# apollo4p register map
Vendor: Ambiq Micro; Series: Apollo; File version: 1.0
CPU: CM4 r1p0, little endian, MPU, FPU, I-cache, D-cache, VTOR, ITCM, DTCM, 3 interrupt priority bits, 0 interrupts
Registers are 32-bit, read-write, reset 0x0 unless marked. A register's access mark holds for its fields unless they carry their own. Offsets are from the block's base; [hi:lo] are bit positions; {n}, {i} and the like mark numbered series.

## DC — Display Controller
Base 0x400A0000
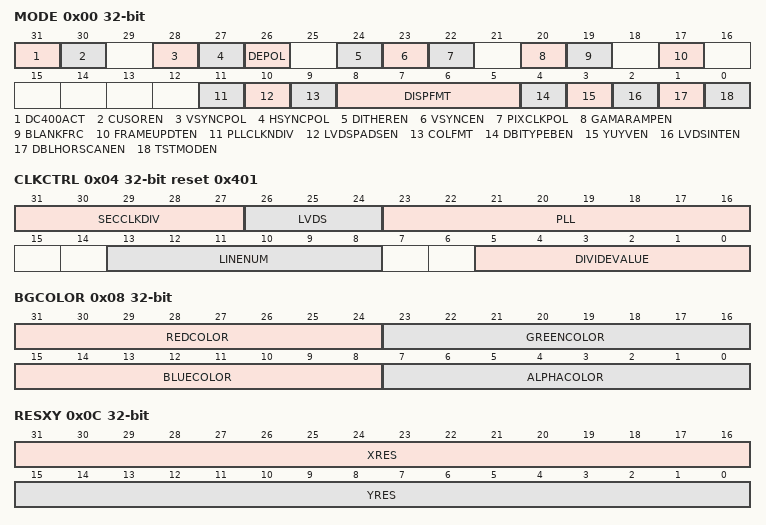
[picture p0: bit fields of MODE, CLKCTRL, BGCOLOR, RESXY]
0x00 MODE — General control register that activates the NEMAp|dc400 controller and various parameters, sets the timing signals' polarity, activates the global look-up table for gamma correction and chooses the output display formats to meet LCD color specifications.
  [31] DC400ACT — When set to 1, the dc400 controller is activated
  [30] CUSOREN — When set to 1, programmable cursor is enabled
  [28] VSYNCPOL — Defines VSYNC polarity
    1=VSYNC_NEG (VSYNC polarity is negative); 0=VSYNC_POS (VSYNC polarity is positive)
  [27] HSYNCPOL — Defines HSYNC polarity
    1=HSYNC_NEG (HSYNC polarity is negative); 0=HSYNC_POS (HSYNC polarity is positive)
  [26] DEPOL — Defines DE polarity
    1=DE_NEG (DE polarity is negative); 0=DE_POS (DE polarity is positive)
  [24] DITHEREN — When set to 1, dithering is enabled
  [23] VSYNCEN — When set to 1, VSYNC for a single cycle per line is enabled
  [22] PIXCLKPOL — Defines Pixel Clock out polarity
    1=POL_NEG (Pixel Clock out polarity is negative); 0=POL_POS (Pixel Clock out polarity is positive)
  [20] GAMARAMPEN — When set to 1, gamma ramp is enabled
  [19] BLANKFRC — When set to 1, forces output to blank
  [17] FRAMEUPDTEN — When set to 1, single frame update is enabled
  [11] PLLCLKNDIV — When set to 1, PLL_CLK is not divided
  [10] LVDSPADSEN — When set to 1, LVDS output pads are enabled
  [9] COLFMT — Output color format:
    1=YUV_EN (YUV/YCbCr format is enabled); 0=RGB_EN (RGB format is enabled)
  [8:5] DISPFMT — Display data format
    0=DPI (DPI Interface); 1=BYTE3 (Byte-3 beat Interface); 2=BYTE4 (Byte-4 beat (RGBX) Interface); 3=SERIAL (Two phase serial 12-bit); 4=LVDS2 (LVDS 24-bit unbalanced single pixel format 2); 5=LVDS1 (LVDS 24-bit unbalanced single pixel format 1); 6=YUYV (YUYV (16-bit mode)); 7=BT656; 8=JDI (JDI MIP)
  [4] DBITYPEBEN — When set to 1, DBI Type-B interface is enabled
  [3] YUYVEN — When set to 1, the following output color formats are enabled : Byte-3 beat Interface enabled, Byte-4 beat (RGBX) Interface enabled, Two phase serial 12-bit enabled, YUYV (16-bit mode) enabled, BT.656 enabled, JDI MIP enabled
  [2] LVDSINTEN — When set to 1, LVDS interface is enabled
  [1] DBLHORSCANEN — When set to 1, double horizontal scan is enabled
  [0] TSTMODEN — When set to 1, test mode is enabled
0x04 CLKCTRL reset 0x401 — Setup proper timing with divisor control bits and specify the number of lines to be prefetched before the start of frame.
  [31:27] SECCLKDIV — Value of secondary clock divider
    0=SDIV_0 (No division); 1=SDIV_1 (No division); {v}=SDIV_{v} (Divided by {v}) (v=2..15)
  [26:24] LVDS — Clock phase shift value for LVDS operation
  [23:16] PLL — Select PLL Clock
  [13:8] LINENUM — Number of lines to be prefetched before starting the frame through DMA. Maximum value is 32
  [5:0] DIVIDEVALUE — Value of first clock divider
    0=FDIV_0 (Divided by 0); {v}=FDIV_{v} (Divided by {v}) (v=2..31)
0x08 BGCOLOR — Specifies the main background color.
  [31:24] REDCOLOR — Color red is used as background color
  [23:16] GREENCOLOR — Color green is used as background color
  [15:8] BLUECOLOR — Color blue is used as background color
  [7:0] ALPHACOLOR — Color alpha is used as background color
0x0C RESXY — Specifies the main X and Y resolutions.
  [31:16] XRES — Value of X resolution in pixels
  [15:0] YRES — Value of Y resolution in pixels
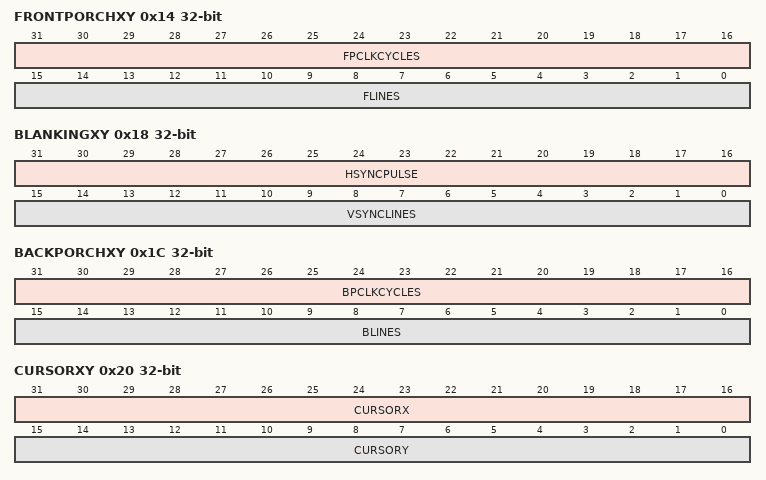
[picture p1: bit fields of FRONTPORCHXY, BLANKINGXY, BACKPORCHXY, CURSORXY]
0x14 FRONTPORCHXY — Specifies the X and Y dimensions for the Front Porch.
  [31:16] FPCLKCYCLES — Specify the pixel clock cycles for the front porch X dimension
  [15:0] FLINES — Specify the number of lines for the front porch Y dimension
0x18 BLANKINGXY — Specifies the X and Y dimensions for the Blanking Period.
  [31:16] HSYNCPULSE — Specify the HSYNC pulse length for the X dimension blanking period
  [15:0] VSYNCLINES — Specify the VSYNC lines for the Y dimension blanking period
0x1C BACKPORCHXY — Specifies the X and Y dimensions for the Back Porch.
  [31:16] BPCLKCYCLES — Specify the pixel clock cycles for the back porch X dimension
  [15:0] BLINES — Specify the number of lines for the back porch Y dimension
0x20 CURSORXY — Specifies the cursor's start X and Y coordinates.
  [31:16] CURSORX — Specify cursor's X dimension
  [15:0] CURSORY — Specify cursor's Y dimension
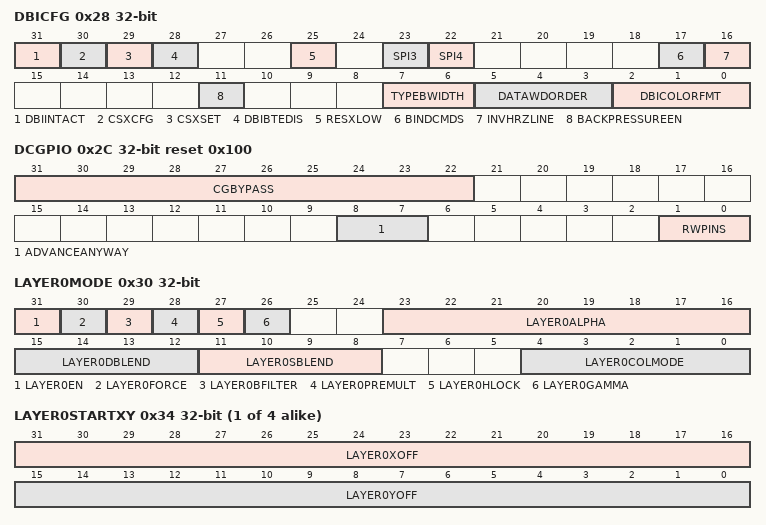
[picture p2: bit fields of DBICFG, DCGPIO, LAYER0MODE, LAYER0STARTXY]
0x28 DBICFG — Register for the configuration DBI Type-B interface and the activation of SPI 3-/4-wire interfaces.
  [31] DBIINTACT — When set to 1, the DBI interface is activated
  [30] CSXCFG — When set to 1, the value of the CSX signal of the DBI interface can be configured from the DBI_CFG[29] register bit
  [29] CSXSET — Sets the value of DBIB_CSX signal:
    1=CSX1 (is set to one if DBI_CFG[29] has the value of one); 0=CSX0 (is set to zero if DBI_CFG[29] has the value of zero)
  [28] DBIBTEDIS — When set to 1, the DBIB_TE signal is disabled
  [25] RESXLOW — When set to 1, drives RESX signal low to reset DBI Type-B interface
  [23] SPI3 — When set to 1, SPI 3-wire interface is enabled
  [22] SPI4 — When set to 1, SPI 4-wire interface is enabled
  [17] BINDCMDS — When set to 1, binds the store commands with the RGB data and two-byte address is sent with each horizontal line
  [16] INVHRZLINE — When set to 1, inverts the bit-order of the horizontal line address (used along with DBI_CFG[17] register bit)
  [11] BACKPRESSUREEN — When set to 1, back pressure support is enabled (not currently supported)
  [7:6] TYPEBWIDTH — Set DBI Type-B interface width (8, 9 or 16 bits) and the serial interface:
    0=INT_16 (16-bit interface); 1=INT_9 (9-bit interface); 2=INT_8 (8-bit interface); 3=INT_SERIAL (Serial interface)
  [5:3] DATAWDORDER — Set the data order of the 8-bit data word:
    {v}=WD_ORDER_OPT{v} (option {v}) (v=0..3)
  [2:0] DBICOLORFMT — Set the color format for DBI interface
    1=DBI_FMT_RGB111 (RGB111 (3 bits/pixel)); 2=DBI_FMT_RGB332 (RGB332 (8 bits/pixel)); 3=DBI_FMT_RGB444 (RGB444 (12 bits/pixel)); 5=DBI_FMT_RGB565 (RGB565 (16 bits/pixel)); 6=DBI_FMT_RGB666 (RGB666 (18 bits/pixel)); 7=DBI_FMT_RGB888 (RGB888 (24 bits/pixel))
0x2C DCGPIO reset 0x100 — General Purpose register: read/write GPIO external pins. This is accumulated as- {CGBYPASS_in,13'd0,ADVANCE_ANYWAY_in,5'd0,GPIO_in}
  [31:22] CGBYPASS — No idea what this is
  [8:7] ADVANCEANYWAY — No idea what this is
  [1:0] RWPINS — These are not implemented
0x30 LAYER0MODE — LAYER0_MODE: Activate and set-up layer 0.
  [31] LAYER0EN — When set to 1, layer n is enabled
  [30] LAYER0FORCE — When set to 1, force alpha with global alpha is enabled
  [29] LAYER0BFILTER — When set to 1, bilinear filtering is enabled
  [28] LAYER0PREMULT — When set to 1, premultiply image alpha is enabled
  [27] LAYER0HLOCK — When set to 1, HLOCK signal on AHB DMAs is asserted
  [26] LAYER0GAMMA — When set to 1, Gamma Look Up Table is enabled
  [23:16] LAYER0ALPHA — Alpha layer global value (0x00-0xFF range)
  [15:12] LAYER0DBLEND — Destination blending function
    0=LAYER0_DBLACK_BLEND (blend black); 1=LAYER0_DWHITE_BLEND (blend white); 2=LAYER0_DALBHAS_BLEND (blend alpha source); 3=LAYER0_DALPHAG_BLEND (blend alpha global); 4=LAYER0_DALPHASG_BLEND (blend alpha source and alpha global); 5=LAYER0_DINVERT_BLEND_SRC (blend inverted source); 6=LAYER0_DINVERT_GLOBAL_BLEND (blend inverted global); 7=LAYER0_DINVERTSG_BLEND (blend inverted source and inverted global); 10=LAYER0_DALPHA_BLEND (blend alpha destination); 13=LAYER0_DINVERT_BLEND_DST (blend inverted destination)
  [11:8] LAYER0SBLEND — Source blending function
    0=LAYER0_SBLACK_BLEND (blend black); 1=LAYER0_SWHITE_BLEND (blend white); 2=LAYER0_SALBHAS_BLEND (blend alpha source); 3=LAYER0_SALPHAG_BLEND (blend alpha global); 4=LAYER0_SALPHASG_BLEND (blend alpha source and alpha global); 5=LAYER0_SINVERT_BLEND_SRC (blend inverted source); 6=LAYER0_SINVERT_GLOBAL_BLEND (blend inverted global); 7=LAYER0_SINVERTSG_BLEND (blend inverted source and inverted global); 10=LAYER0_SALPHA_BLEND (blend alpha destination); 13=LAYER0_SINVERT_BLEND_DST (blend inverted destination)
  [4:0] LAYER0COLMODE — Color mode
    0=LAYER0CM_LUTBLE (8-bit color palette look-up table (LUT8)); 1=LAYER0CM_RGBX5551 (16-bit RGBX5551 color format); 2=LAYER0CM_RGBX8888 (32-bit RGBX8888 color format); 4=LAYER0CM_RGB332 (8-bit RGB332 color format); 5=LAYER0CM_RGB565 (16-bit RGB565 color format); 6=LAYER0CM_XRGB8888 (32-bit XRGB8888 color format); 7=LAYER0CM_L8 (L8 Grayscale/Palette format); 8=LAYER0CM_L1 (L1 Grayscale/Palette format); 9=LAYER0CM_L4 (L4 Grayscale/Palette format); 10=LAYER0CM_YUYV (color format); 11=LAYER0CM_RBG (24-bit RGB color format); 12=LAYER0CM_YUY2 (YUY2 color format); 13=LAYER0CM_ABGR8888 (32-bit ABGR8888 color format); 14=LAYER0CM_BGRA8888 (32-bit BGRA8888 color format); 16=LAYER0CM_Video (Video 420 Mode); 17=LAYER0CM_Trilinear (Trilinea 420 Video Mode)
{0x34+0x20*i} LAYER{i}STARTXY (i=0..3) — X and Y start dimensions of layer {i}.
  [31:16] LAYER{i}XOFF — Specify the pixel offset of the starting X dimension of layer {i}
  [15:0] LAYER{i}YOFF — Specify the pixel offset of the starting Y dimension of layer {i}
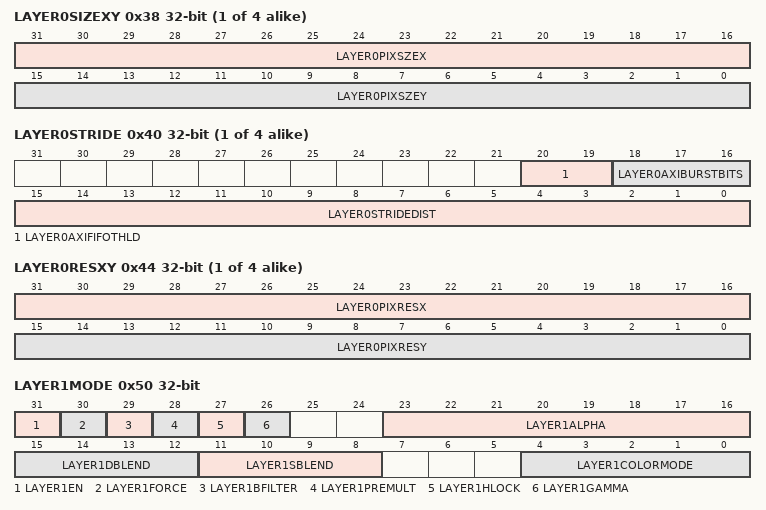
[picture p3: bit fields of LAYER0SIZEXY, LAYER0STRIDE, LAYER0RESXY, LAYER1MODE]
{0x38+0x20*i} LAYER{i}SIZEXY (i=0..3) — X and Y size of layer {i}.
  [31:16] LAYER{i}PIXSZEX — Specify the pixel size of the layer {i} in the X dimension
  [15:0] LAYER{i}PIXSZEY — Specify the pixel size of the layer {i} in the Y dimension
{0x3C+0x20*i} LAYER{i}ADDR (i=0..3) — The start address of the framebuffer to be accessed by layer {i}.
  [31:0] LAYER{i}STARTADDRFBUF — Specify the start address of framebuffer for each layer {i}.
{0x40+0x20*i} LAYER{i}STRIDE (i=0..3) — Specify the stride and the AXI bus burst of layer {i}.
  [20:19] LAYER{i}AXIFIFOTHLD — Specify the AXI fifo threshold burst start in layer {i}
    0=LAYER{i}_BURST_HALF_SZ (half fifo (default)); 1=LAYER{i}_BURST_2 (2 burst-size); 2=LAYER{i}_BURST_4 (4 burst-size); 3=LAYER{i}_BURST_8 (8 burst-size)
  [18:16] LAYER{i}AXIBURSTBITS — Specify the AXI bits per burst in layer {i}
    0=LAYER{i}_BEATS_DEF (16-beats (default)); 1=LAYER{i}_BEATS_2 (2-beats); 2=LAYER{i}_BEATS_4 (4-beats); 3=LAYER{i}_BEATS_8 (8-beats); 4=LAYER{i}_BEATS_16 (16-beats (CHECK mistake?)); 5=LAYER{i}_BEATS_32 (32-beats (AXI4 only)); 6=LAYER{i}_BEATS_64 (64-beats (AXI4 only)); 7=LAYER{i}_BEATS_128 (128-beats (AXI4 only))
  [15:0] LAYER{i}STRIDEDIST — Specify the stride, which is the distance from line to line in bytes for each layer {i} memory
{0x44+0x20*i} LAYER{i}RESXY (i=0..3) — X and Y dimensions for the resolution of layer {i}.
  [31:16] LAYER{i}PIXRESX — Specify the layer n pixel resolution in the X dimension
  [15:0] LAYER{i}PIXRESY — Specify the layer n pixel resolution in the Y dimension
0x48 LAYER0SCALEX — Scale X factor of layer 0.
  [31:0] LAYER0XFACTOR — Specify the scale X factor of layer n (4.14 fixed point number)
{0x4C+0x20*i} LAYER{i}SCALEY (i=0..3) — Scale Y factor of layer {i}.
  [31:0] LAYER{i}YFACTOR — Specify the scale Y factor of layer n (4.14 fixed point number)
0x50 LAYER1MODE — Activate and set-up layer 1.
  [31] LAYER1EN — When set to 1, layer n is enabled
  [30] LAYER1FORCE — When set to 1, force alpha with global alpha is enabled
  [29] LAYER1BFILTER — When set to 1, bilinear filtering is enabled
  [28] LAYER1PREMULT — When set to 1, premultiply image alpha is enabled
  [27] LAYER1HLOCK — When set to 1, HLOCK signal on AHB DMAs is asserted
  [26] LAYER1GAMMA — When set to 1, Gamma Look Up Table is enabled
  [23:16] LAYER1ALPHA — Alpha layer global value (0x00-0xFF range)
  [15:12] LAYER1DBLEND — Destination blending function
    0=LAYER1_DBLACK_BLEND (blend black); 1=LAYER1_DWHITE_BLEND (blend white); 2=LAYER1_DALBHAS_BLEND (blend alpha source); 3=LAYER1_DALPHAG_BLEND (blend alpha global); 4=LAYER1_DALPHASG_BLEND (blend alpha source and alpha global); 5=LAYER1_DINVERT_BLEND_SRC (blend inverted source); 6=LAYER1_DINVERT_GLOBAL_BLEND (blend inverted global); 7=LAYER1_DINVERTSG_BLEND (blend inverted source and inverted global); 10=LAYER1_DALPHA_BLEND (blend alpha destination); 13=LAYER1_DINVERT_BLEND_DST (blend inverted destination)
  [11:8] LAYER1SBLEND — Source blending function
    0=LAYER1_SBLACK_BLEND (blend black); 1=LAYER1_SWHITE_BLEND (blend white); 2=LAYER1_SALBHAS_BLEND (blend alpha source); 3=LAYER1_SALPHAG_BLEND (blend alpha global); 4=LAYER1_SALPHASG_BLEND (blend alpha source and alpha global); 5=LAYER1_SINVERT_BLEND_SRC (blend inverted source); 6=LAYER1_SINVERT_GLOBAL_BLEND (blend inverted global); 7=LAYER1_SINVERTSG_BLEND (blend inverted source and inverted global); 10=LAYER1_SALPHA_BLEND (blend alpha destination); 13=LAYER1_SINVERT_BLEND_DST (blend inverted destination)
  [4:0] LAYER1COLORMODE — Color mode
    0=LAYER1_LUTBLE (8-bit color palette look-up table (LUT8)); 1=LAYER1_RGBX5551 (16-bit RGBX5551 color format); 2=LAYER1_RGBX8888 (32-bit RGBX8888 color format); 4=LAYER1_RGB332 (8-bit RGB332 color format); 5=LAYER1_RGB565 (16-bit RGB565 color format); 6=LAYER1_XRGB8888 (32-bit XRGB8888 color format); 7=LAYER1_L8 (L8 Grayscale/Palette format); 8=LAYER1_L1 (L1 Grayscale/Palette format); 9=LAYER1_L4 (L4 Grayscale/Palette format); 10=LAYER1_YUYV (YUYV color format); 11=LAYER1_RGB (24-bit RGB color format); 12=LAYER1_YUY2 (YUY2 color format); 13=LAYER1_ABGR8888 (32-bit ABGR8888 color format); 14=LAYER1_BGRA8888 (32-bit BGRA8888 color format); 16=LAYER1_VIDEO420 (Video 420 Mode); 17=LAYER1_TRILIN420 (Trilinear 420 Video Mode)
{0x48+0x20*i} LAYER{i}SCALEX (i=1..3) — Scale X factor of layer {i}.
  [31:0] LAYER{i}XFACTOR — Specify the scale X factor of layer n (4.14 fixed point number)
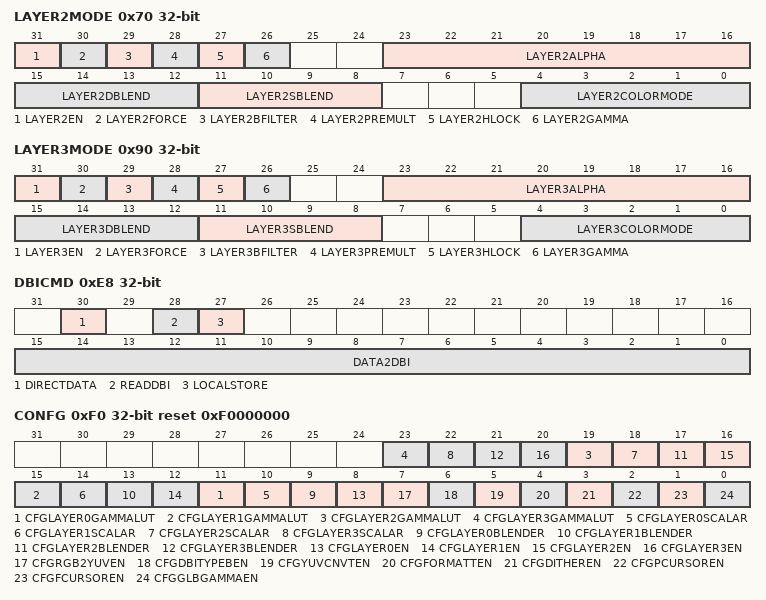
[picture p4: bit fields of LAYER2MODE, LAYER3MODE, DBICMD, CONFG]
0x70 LAYER2MODE — Activate and set-up layer 2.
  [31] LAYER2EN — When set to 1, layer n is enabled
  [30] LAYER2FORCE — When set to 1, force alpha with global alpha is enabled
  [29] LAYER2BFILTER — When set to 1, bilinear filtering is enabled
  [28] LAYER2PREMULT — When set to 1, premultiply image alpha is enabled
  [27] LAYER2HLOCK — When set to 1, HLOCK signal on AHB DMAs is asserted
  [26] LAYER2GAMMA — When set to 1, Gamma Look Up Table is enabled
  [23:16] LAYER2ALPHA — Alpha layer global value (0x00-0xFF range)
  [15:12] LAYER2DBLEND — Destination blending function
    0=LAYER2_DBLACK_BLEND (blend black); 1=LAYER2_DWHITE_BLEND (blend white); 2=LAYER2_DALBHAS_BLEND (blend alpha source); 3=LAYER2_DALPHAG_BLEND (blend alpha global); 4=LAYER2_DALPHASG_BLEND (blend alpha source and alpha global); 5=LAYER2_DINVERT_BLEND_SRC (blend inverted source); 6=LAYER2_DINVERT_GLOBAL_BLEND (blend inverted global); 7=LAYER2_DINVERTSG_BLEND (blend inverted source and inverted global); 10=LAYER2_DALPHA_BLEND (blend alpha destination); 13=LAYER2_DINVERT_BLEND_DST (blend inverted destination)
  [11:8] LAYER2SBLEND — Source blending function
    0=LAYER2_SBLACK_BLEND (blend black); 1=LAYER2_SWHITE_BLEND (blend white); 2=LAYER2_SALBHAS_BLEND (blend alpha source); 3=LAYER2_SALPHAG_BLEND (blend alpha global); 4=LAYER2_SALPHASG_BLEND (blend alpha source and alpha global); 5=LAYER2_SINVERT_BLEND_SRC (blend inverted source); 6=LAYER2_SINVERT_GLOBAL_BLEND (blend inverted global); 7=LAYER2_SINVERTSG_BLEND (blend inverted source and inverted global); 10=LAYER2_SALPHA_BLEND (blend alpha destination); 13=LAYER2_SINVERT_BLEND_DST (blend inverted destination)
  [4:0] LAYER2COLORMODE — Color mode
    0=LAYER2_LUTBLE (8-bit color palette look-up table (LUT8)); 1=LAYER2_RGBX5551 (16-bit RGBX5551 color format); 2=LAYER2_RGBX8888 (32-bit RGBX8888 color format); 4=LAYER2_RGB332 (8-bit RGB332 color format); 5=LAYER2_RGB565 (16-bit RGB565 color format); 6=LAYER2_XRGB8888 (32-bit XRGB8888 color format); 7=LAYER2_L8 (L8 Grayscale/Palette format); 8=LAYER2_L1 (L1 Grayscale/Palette format); 9=LAYER2_L4 (L4 Grayscale/Palette format); 10=LAYER2_YUYV (YUYV color format); 11=LAYER2_RGB (24-bit RGB color format); 12=LAYER2_YUY2 (YUY2 color format); 13=LAYER2_ABGR8888 (32-bit ABGR8888 color format); 14=LAYER2_BGRA8888 (32-bit BGRA8888 color format); 16=LAYER2_VIDEO420 (Video 420 Mode); 17=LAYER2_TRILIN420 (Trilinear 420 Video Mode)
0x90 LAYER3MODE — Activate and set-up layer 3.
  [31] LAYER3EN — When set to 1, layer n is enabled
  [30] LAYER3FORCE — When set to 1, force alpha with global alpha is enabled
  [29] LAYER3BFILTER — When set to 1, bilinear filtering is enabled
  [28] LAYER3PREMULT — When set to 1, premultiply image alpha is enabled
  [27] LAYER3HLOCK — When set to 1, HLOCK signal on AHB DMAs is asserted
  [26] LAYER3GAMMA — When set to 1, Gamma Look Up Table is enabled
  [23:16] LAYER3ALPHA — Alpha layer global value (0x00-0xFF range)
  [15:12] LAYER3DBLEND — Destination blending function
    0=LAYER3_DBLACK_BLEND (blend black); 1=LAYER3_DWHITE_BLEND (blend white); 2=LAYER3_DALBHAS_BLEND (blend alpha source); 3=LAYER3_DALPHAG_BLEND (blend alpha global); 4=LAYER3_DALPHASG_BLEND (blend alpha source and alpha global); 5=LAYER3_DINVERT_BLEND_SRC (blend inverted source); 6=LAYER3_DINVERT_GLOBAL_BLEND (blend inverted global); 7=LAYER3_DINVERTSG_BLEND (blend inverted source and inverted global); 10=LAYER3_DALPHA_BLEND (blend alpha destination); 13=LAYER3_DINVERT_BLEND_DST (blend inverted destination)
  [11:8] LAYER3SBLEND — Source blending function
    0=LAYER3SBLACKBLEND (layer 3 black blend register. blend black); 1=LAYER3SWHITEBLEND (blend white); 2=LAYER3SALBHASBLEND (blend alpha source); 3=LAYER3SALPHAGBLEND (blend alpha global); 4=LAYER3SALPHASGBLEND (blend alpha source and alpha global); 5=LAYER3_SINVERT_BLEND_SRC (blend inverted source); 6=LAYER3SINVERTGLOBALBLEND (blend inverted global); 7=LAYER3SINVERTSGBLEND (blend inverted source and inverted global); 10=LAYER3SALPHABLEND (blend alpha destination); 13=LAYER3_SINVERT_BLEND_DST (blend inverted destination)
  [4:0] LAYER3COLORMODE — Color mode
    0=LAYER3_LUTBLE (8-bit color palette look-up table (LUT8)); 1=LAYER3_RGBX5551 (16-bit RGBX5551 color format); 2=LAYER3_RGBX8888 (32-bit RGBX8888 color format); 4=LAYER3_RGB332 (8-bit RGB332 color format); 5=LAYER3_RGB565 (16-bit RGB565 color format); 6=LAYER3_XRGB8888 (32-bit XRGB8888 color format); 7=LAYER3_L8 (L8 Grayscale/Palette format); 8=LAYER3_L1 (L1 Grayscale/Palette format); 9=LAYER3_L4 (L4 Grayscale/Palette format); 10=LAYER3_YUYV (YUYV color format); 11=LAYER3_RGB (24-bit RGB color format); 12=LAYER3_YUY2 (YUY2 color format); 13=LAYER3_ABGR8888 (32-bit ABGR8888 color format); 14=LAYER3_BGRA8888 (32-bit BGRA8888 color format); 16=LAYER3_VIDEO420 (Video 420 Mode); 17=LAYER3_TRILIN42 (Trilinear 420 Video Mode)
0xE8 DBICMD — Register to read/write commands from/to DBI Type-B interface.
  [30] DIRECTDATA — Send direct data of type 'command' to the DBI interface
  [28] READDBI — Read from DBI interface
  [27] LOCALSTORE — When set to 1, bits [15:0] are locally stored as base address of the horizontal line; it is used along with the DBI_CFG[17:16] register bits for the SPI interface
  [15:0] DATA2DBI — Data to send to the DBI interface
0xEC DBIRDAT — Data read by DBI Type-B interface are stored in the DBI_RDAT register.
  [31:0] READTYPEB — Read data from DBI Type-B interface
0xF0 CONFG reset 0xF0000000 — Information of the layers n activation and setup.
  [4n+11] CFGLAYER{n}GAMMALUT (n=0..3) — Indicates that layer {n} has gamma LUT
  [4n+10] CFGLAYER{n}SCALAR (n=0..3) — Indicates that layer {n} has scaler
  [4n+9] CFGLAYER{n}BLENDER (n=0..3) — Indicates that layer {n} has blender
  [4n+8] CFGLAYER{n}EN (n=0..3) — Indicates that layer {n} is enabled
  [7] CFGRGB2YUVEN — Indicates that RGB to YUV converter is enabled
  [6] CFGDBITYPEBEN — Indicates that DBI Type-B interface is enabled
  [5] CFGYUVCNVTEN — Indicates that high quality YUV converter is enabled
  [4] CFGFORMATTEN — Indicates that formatting is enabled
  [3] CFGDITHEREN — Indicates that dithering is enabled
  [2] CFGPCURSOREN — Indicates that programmable cursor is enabled
  [1] CFGFCURSOREN — Indicates that fixed cursor is enabled
  [0] CFGGLBGAMMAEN — Indicates that Global Gamma/Palette is enabled
0xF4 IDREG — Identification Register.
  [31:0] DCID — Fixed value for DC ID
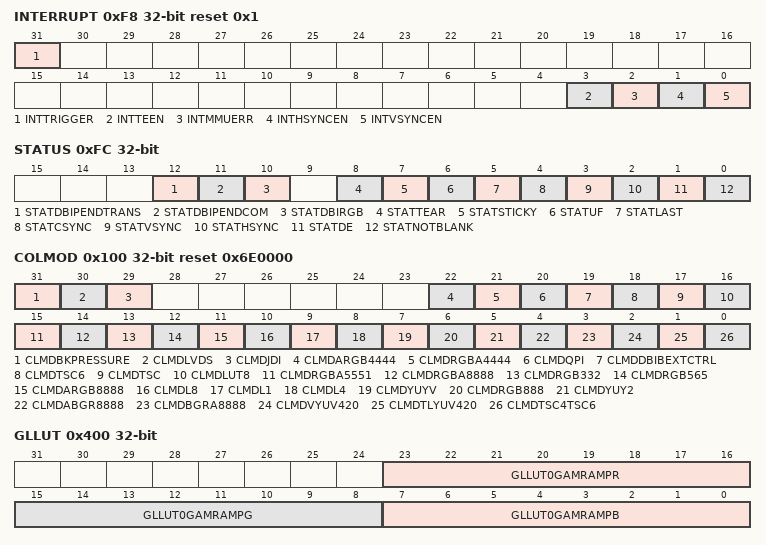
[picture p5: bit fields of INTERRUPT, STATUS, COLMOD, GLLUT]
0xF8 INTERRUPT reset 0x1 — Register interrupts enabled, level or edge enabled.
  [31] INTTRIGGER — Interrupt request trigger control
    1=LEVEL (Level triggering is enabled); 0=EDGE (Edge triggering is enabled)
  [3] INTTEEN — When set to 1, TE interrupt enabled
  [2] INTMMUERR — When set to 1, MMU error interrupt enabled
  [1] INTHSYNCEN — When set to 1, HSYNC interrupt enabled
  [0] INTVSYNCEN — When set to 1, VSYNC interrupt enabled
0xFC STATUS — DSI Status register (interrupt and pending activity)
  [12] STATDBIPENDTRANS — Indicates pending output transaction in DBI interface
  [11] STATDBIPENDCOM — Indicates pending commands in DBI interface
  [10] STATDBIRGB — Indicates pending RGB data in DBI interface
  [8] STATTEAR — Indicates DBI Type-B tearing effect
  [7] STATSTICKY — Indicates sticky underflow. This bit clears when interrupt register is written
  [6] STATUF — Indicates current underflow
  [5] STATLAST — Indicates that the last row is currently displayed
  [4] STATCSYNC — Indicates the CSYNC signal status (0 or 1) at the current time of reading
  [3] STATVSYNC — Indicates the VSYNC signal status and the tearing e?ect signal status (0 or 1) at the current time of reading
  [2] STATHSYNC — Indicates the HSYNC signal status (0 or 1) at the current time of reading
  [1] STATDE — Indicates the DE signal status (0 or 1) at the current time of reading
  [0] STATNOTBLANK — Indicates that the controller is not in active vertical blanking
0x100 COLMOD reset 0x6E0000 — Color mode status register indicating formats/back pressure are enabled.
  [31] CLMDBKPRESSURE — Indicates that back pressure support for the DBI Type B interface is enabled
  [30] CLMDLVDS — Indicates that back pressure support for the DBI Type B interface is enabled
  [29] CLMDJDI — Indicates that back pressure support for the DBI Type B interface is enabled
  [22] CLMDARGB4444 — Indicates that back pressure support for the DBI Type B interface is enabled
  [21] CLMDRGBA4444 — Indicates that back pressure support for the DBI Type B interface is enabled
  [20] CLMDQPI — Indicates that back pressure support for the DBI Type B interface is enabled
  [19] CLMDDBIBEXTCTRL — Indicates that back pressure support for the DBI Type B interface is enabled
  [18] CLMDTSC6 — Indicates that back pressure support for the DBI Type B interface is enabled
  [17] CLMDTSC — Indicates that back pressure support for the DBI Type B interface is enabled
  [16] CLMDLUT8 — Indicates that the LUT8 color format is enabled
  [15] CLMDRGBA5551 — Indicates that the RGBA5551 16-bit color format is enabled
  [14] CLMDRGBA8888 — Indicates that the RGBA8888 32-bit color format is enabled
  [13] CLMDRGB332 — Indicates that the RGB332 8-bit color format is enabled
  [12] CLMDRGB565 — Indicates that the RGB565 16-bit color format is enabled
  [11] CLMDARGB8888 — Indicates that the ARGB8888 32-bit color format is enabled
  [10] CLMDL8 — Indicates that the L8 color format is enabled
  [9] CLMDL1 — Indicates that the L1 color format is enabled
  [8] CLMDL4 — Indicates that the L4 color format is enabled
  [7] CLMDYUYV — Indicates that the YUYV color format is enabled
  [6] CLMDRGB888 — Indicates that the RGB888 24-bit color format is enabled
  [5] CLMDYUY2 — Indicates that the YUY2 color format is enabled
  [4] CLMDABGR8888 — Indicates that the ABGR8888 32-bit color format is enabled
  [3] CLMDBGRA8888 — Indicates that the BGRA8888 32-bit color format is enabled
  [2] CLMDVYUV420 — Indicates that the V_YUV420 color format is enabled
  [1] CLMDTLYUV420 — Indicates that the TLYUV420 color format is enabled
  [0] CLMDTSC4TSC6 — Indicates that the TSc4/TSc6 propietary color format is enabled
0x184 CRC — if cyclic redundancy errors occur, they are written in the CRC register.
  [31:0] CRCREG — CRC value if CRC error exists
0x400 GLLUT — R[0]G[0]B[0] thru R[255]G[255]B[255] Global palette, gamma correction memory region where x starts at 0 thru 255.Access to all 256 registers is best accomplished by passing an index via a macro. e.g. pseudocode #define DC_L0LUT(n) (*((volatile uint32_t*)(&L0LUT + (4*n))))
  [23:16] GLLUT0GAMRAMPR — Gamma ramp red bits
  [15:8] GLLUT0GAMRAMPG — Gamma ramp green bits
  [7:0] GLLUT0GAMRAMPB — Gamma ramp blue bits
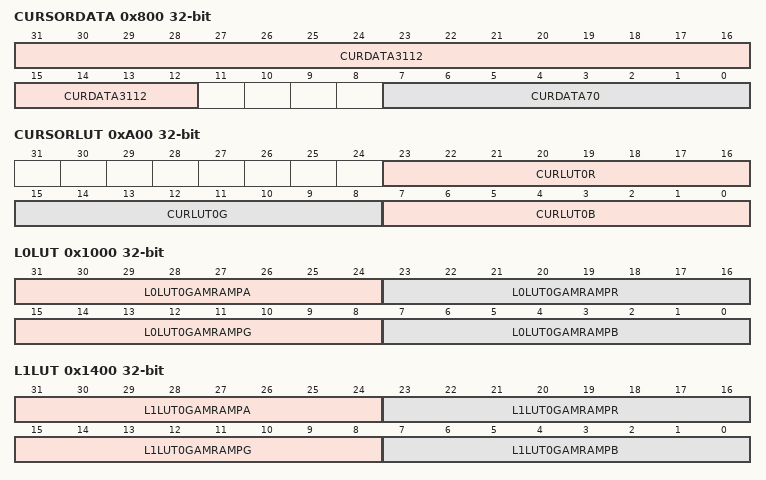
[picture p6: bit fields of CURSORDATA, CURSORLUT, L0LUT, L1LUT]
0x800 CURSORDATA — Color values for the pixel cursor that are used with the Cursor LUT where x starts at 0 thru 127.Access to all 16 registers is best accomplished by passing an index via a macro. e.g. pseudocode #define DC_CURSORDATA(n) (*((volatile uint32_t*)(&CURSORDATA + (4*n))))
  [31:12] CURDATA3112 — Pixel 'xy' color look up bits
  [7:0] CURDATA70 — Pixel 'xy' color look up bits
0xA00 CURSORLUT — R[0]G[0]B[0] thru R[15]G[15]B[15] Cursor Look-up Table where x starts at 0 thru 15.Access to all 16 registers is best accomplished by passing an index via a macro. e.g. pseudocode #define DC_CURSORLUT(n) (*((volatile uint32_t*)(&CURSORLUT + (4*n))))
  [23:16] CURLUT0R — Cursor LUT red bits
  [15:8] CURLUT0G — Cursor LUT green bits
  [7:0] CURLUT0B — Cursor LUT blue bits
0x1000 L0LUT — A[0]R[0]G[0]B[0] thru A[255]R[255]G[255]B[255]. Layer 0 palette,gamma correction memory region where x starts at 0 thru 255.
  [31:24] L0LUT0GAMRAMPA — Gamma ramp alpha bits
  [23:16] L0LUT0GAMRAMPR — Gamma ramp red bits
  [15:8] L0LUT0GAMRAMPG — Gamma ramp green bits
  [7:0] L0LUT0GAMRAMPB — Gamma ramp blue bits
0x1400 L1LUT — A[0]R[0]G[0]B[0] thru A[255]R[255]G[255]B[255] Layer 1 palette,gamma correction memory region where x starts at 0 thru 255.Access to all 256 registers is best accomplished by passing an index via a macro. e.g. pseudocode #define DC_L1LUT(n) (*((volatile uint32_t*)(&L1LUT + (4*n))))
  [31:24] L1LUT0GAMRAMPA — Gamma ramp alpha bits
  [23:16] L1LUT0GAMRAMPR — Gamma ramp red bits
  [15:8] L1LUT0GAMRAMPG — Gamma ramp green bits
  [7:0] L1LUT0GAMRAMPB — Gamma ramp blue bits
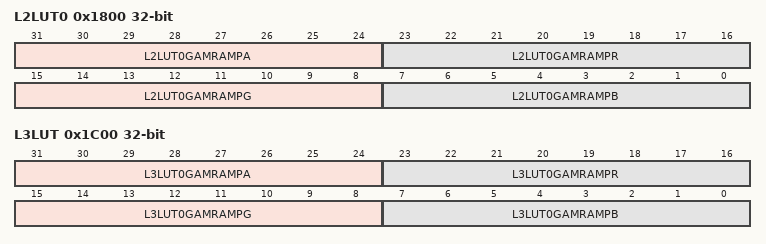
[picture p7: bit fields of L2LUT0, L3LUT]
0x1800 L2LUT0 — A[0]R[0]G[0]B[0] thru A[255]R[255]G[255]B[255] Layer 2 palette,gamma correction memory region where x starts at 0 thru 255.Access to all 256 registers is best accomplished by passing an index via a macro. e.g. pseudocode #define DC_L2LUT(n) (*((volatile uint32_t*)(&L2LUT + (4*n))))
  [31:24] L2LUT0GAMRAMPA — Gamma ramp alpha bits
  [23:16] L2LUT0GAMRAMPR — Gamma ramp red bits
  [15:8] L2LUT0GAMRAMPG — Gamma ramp green bits
  [7:0] L2LUT0GAMRAMPB — Gamma ramp blue bits
0x1C00 L3LUT — A[0]R[0]G[0]B[0] thru A[255]R[255]G[255]B[255] Layer 3 palette,gamma correction memory region where x starts at 0 thru 255.Access to all 256 registers is best accomplished by passing an index via a macro. e.g. pseudocode #define DC_L3LUT(n) (*((volatile uint32_t*)(&L3LUT + (4*n))))
  [31:24] L3LUT0GAMRAMPA — Gamma ramp alpha bits
  [23:16] L3LUT0GAMRAMPR — Gamma ramp red bits
  [15:8] L3LUT0GAMRAMPG — Gamma ramp green bits
  [7:0] L3LUT0GAMRAMPB — Gamma ramp blue bits

## Notices in the file
Copyright (C) 2012-2014 ARM Limited. All rights reserved.
Purpose: System Viewer Description (SVD) Example (Schema Version 1.1)
This is a description of a none-existent and incomplete device
for demonstration purposes only.
Redistribution and use in source and binary forms, with or without
modification, are permitted provided that the following conditions are met:
- Redistributions of source code must retain the above copyright
notice, this list of conditions and the following disclaimer.
- Redistributions in binary form must reproduce the above copyright
notice, this list of conditions and the following disclaimer in the
documentation and/or other materials provided with the distribution.
- Neither the name of ARM nor the names of its contributors may be used
to endorse or promote products derived from this software without
specific prior written permission.
THIS SOFTWARE IS PROVIDED BY THE COPYRIGHT HOLDERS AND CONTRIBUTORS "AS IS"
AND ANY EXPRESS OR IMPLIED WARRANTIES, INCLUDING, BUT NOT LIMITED TO, THE
IMPLIED WARRANTIES OF MERCHANTABILITY AND FITNESS FOR A PARTICULAR PURPOSE
ARE DISCLAIMED. IN NO EVENT SHALL COPYRIGHT HOLDERS AND CONTRIBUTORS BE
LIABLE FOR ANY DIRECT, INDIRECT, INCIDENTAL, SPECIAL, EXEMPLARY, OR
CONSEQUENTIAL DAMAGES (INCLUDING, BUT NOT LIMITED TO, PROCUREMENT OF
SUBSTITUTE GOODS OR SERVICES; LOSS OF USE, DATA, OR PROFITS; OR BUSINESS
INTERRUPTION) HOWEVER CAUSED AND ON ANY THEORY OF LIABILITY, WHETHER IN
CONTRACT, STRICT LIABILITY, OR TORT (INCLUDING NEGLIGENCE OR OTHERWISE)
ARISING IN ANY WAY OUT OF THE USE OF THIS SOFTWARE, EVEN IF ADVISED OF THE
POSSIBILITY OF SUCH DAMAGE.
